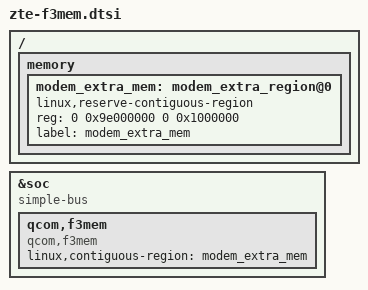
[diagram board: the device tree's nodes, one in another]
/ {
	memory {
		#address-cells = <2>;
		#size-cells = <2>;

		modem_extra_mem: modem_extra_region@0 {
			linux,reserve-contiguous-region;
			reg = <0 0x9e000000 0 0x1000000>;
			label = "modem_extra_mem";
		};
	};
};


&soc {
	#address-cells = <1>;
	#size-cells = <1>;
	ranges = <0 0 0 0xffffffff>;
	compatible = "simple-bus";

	qcom,f3mem {
		compatible = "qcom,f3mem";
	       linux,contiguous-region = <&modem_extra_mem>;
	};
};
